# RA register map
Vendor: Renesas; Series: All Chips; File version: x.xx
Registers are 32-bit, read-write, reset 0x0 unless marked. A register's access mark holds for its fields unless they carry their own. Offsets are from the block's base; [hi:lo] are bit positions; lines under a group give offsets from that group; {n}, {i} and the like mark numbered series; 'fields as' and 'values as' point back to an identical list.

## R_GLCDC — Graphics LCD Controller
Base 0x400E0000
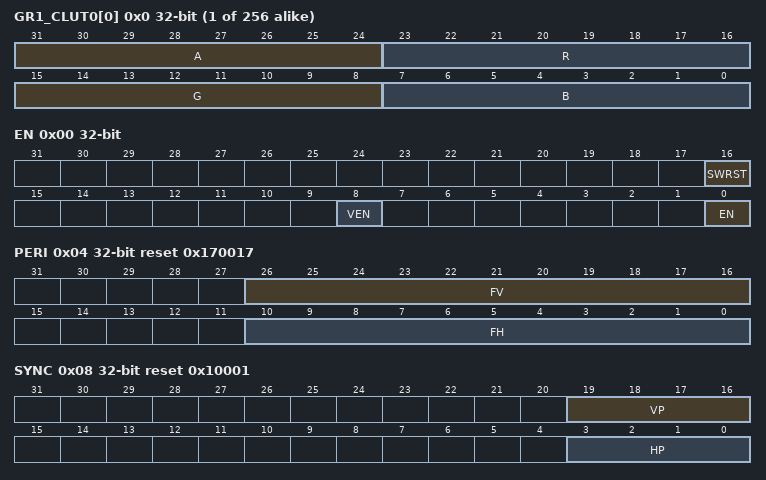
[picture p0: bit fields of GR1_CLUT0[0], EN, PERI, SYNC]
{0x0+4i} GR1_CLUT0[{i}] (i=0..255) reset not defined — Color Palette 0 Plane for Graphics 1 Plane
  [31:24] A — Alpha Blending Value of Color Palette n Plane for Graphics m Plane
  [23:16] R — R Value of Color Palette n Plane for Graphics m Plane
  [15:8] G — G Value of Color Palette n Plane for Graphics m Plane
  [7:0] B — B Value of Color Palette n Plane for Graphics m Plane
0x400 GR1_CLUT1[%s] reset not defined — Color Palette 1 Plane for Graphics 1 Plane
0x800 GR2_CLUT0[%s] reset not defined — Color Palette 0 Plane for Graphics 2 Plane
0xC00 GR2_CLUT1[%s] reset not defined — Color Palette 1 Plane for Graphics 2 Plane
0x1000 BG group — Background Registers
  0x00 EN — Background Plane Setting Operation Control Register
    [16] SWRST — Entire module SW reset control
      1=Releases the entire module from the SW reset state; 0=Places the entire module in the SW reset state
    [8] VEN write-1-sets read-modifies — Control of LCDC internal register value reflection to internal operations
      1=Enables; 0=Disables(Cleared to 0 by an internal source)
    [0] EN — Background plane generation module operation enable
      1=Enables operation; 0=Disables operation
  0x04 PERI reset 0x170017 — Background Plane Setting Free-Running Period Register
    [26:16] FV range 0x013..0x3FF — Background plane vertical synchronization signal period on the basis of line.
      other=FV (FV lines.The valid range is 0x013 to 0x3FF.)
    [10:0] FH range 0x017..0x3FF — Background plane horizontal synchronization signal period on the basis of pixel clock (PXCLK).
      other=FH (FH lines. The valid range is 0x017 to 0x3FF.)
  0x08 SYNC reset 0x10001 — Background Plane Setting Synchronization Position Register
    [19:16] VP — Background plane vertical synchronization signal assertion position on the basis of line.
      0=Setting prohibited; other=others ((VP)th line)
    [3:0] HP — Background plane horizontal synchronization signal assertion position on the basis of pixel clock (PXCLK).
      0=Setting prohibited; other=others ((HP)th line (pixels))
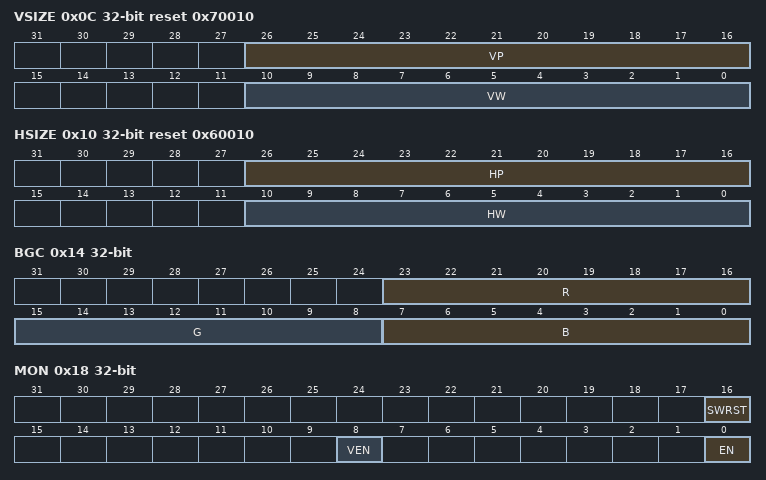
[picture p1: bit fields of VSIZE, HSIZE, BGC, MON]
  0x0C VSIZE reset 0x70010 — Background Plane Setting Full Image Vertical Size Register
    [26:16] VP range 0x0003..0x3EF — Background plane vertical valid pixel start position on the basis of line
      other=VP (VP lines. The valid range is 0x003 to 0x3EF.)
    [10:0] VW range 0x0010..0x03FC — Background plane vertical valid pixel width on the basis of line
      other=VW (VW lines. The valid range is 0x010 to 0x3F0.)
  0x10 HSIZE reset 0x60010 — Background Plane Setting Full Image Horizontal Size Register
    [26:16] HP range 0x006..0x3EE — Background plane horizontal valid pixel start position on the basis of pixel clock (PXCLK).
      other=HP (HP cycle(pixel). The valid range is 0x006 to 0x3EE.)
    [10:0] HW range 0x010..0x3F8 — Background plane horizontall valid pixel width on the basis of pixel clock (PXCLK) Note: When serial RGB is selected as the output format for the output control block, add two to the horizontal enable signal width and set the resulting value to this field.
      other=HW (HW cycles. The valid range is 0x010 to 0x3F8.)
  0x14 BGC — Background Plane Setting Background Color Register
    [23:16] R — R value for background plane valid pixel area. Unsigned; 8-bit integer.
    [15:8] G — G value for background plane valid pixel area Unsigned; 8-bit integer
    [7:0] B — B value for background plane valid pixel area Unsigned; 8-bit integer
  0x18 MON ro — Background Plane Setting Status Monitor Register
    [16] SWRST — Entire module SW reset state monitor.
      1=The entire module is released from the SW reset state; 0=The entire module is in the SW reset state
    [8] VEN — Entire module internal operation reflection control signal monitor. The signal state for controlling reflection of the register values to the internal operations upon assertion of the vertical synchronization signal.
      1=The signal for controlling reflection of the register values to the internal operations upon assertion of the vertical synchronization signal is asserted; 0=The signal for controlling reflection of the register values to the internal operations upon assertion of the vertical synchronization signal is negated
    [0] EN — Background plane generation module operation state monitor.
      1=Operation is in progress; 0=Operation is stopped
{0x1100+0x100*i} GR[{i}] (i=0..1) group — Layer Registers
  0x00 VEN — Graphics Register Update Control Register
    [0] PVEN write-0-clears read-modifies — Control of graphics n module register value reflection to internal operations. Reflection of the register values to the internal operation at the assertion of the vertical synchronization signal (VS).
      1=Enables reflection of the register values to the internal operation at the assertion of the vertical synchronization signal (VS); 0=Disables reflection of the register values to the internal operation at the assertion of the vertical synchronization signal (VS)
  0x04 FLMRD — Graphics Frame Buffer Read Control Register
    [0] RENB — Graphics data (frame buffer data) read enable.
      1=Enables reading; 0=Disables reading
  0x08 FLM1 ro reset 0x3 — Graphics Frame Buffer Control Register 1
    [1:0] BSTMD — Burst transfer control for graphics data (frame buffer data) access
      3=16-beat increment burst transfer (64-byte boundary); other=others (Setting prohibited.)
  0x0C FLM2 — Graphics Frame Buffer Control Register 2
    [31:0] BASE — Base address for accessing graphics data (frame buffer data) Set the head address in the frame buffer where graphics data is to be stored. GRn_FLM2.BASE[5:0] should be fixed to 0 during 64-byte burst transfer.
  0x10 FLM3 — Graphics Frame Buffer Control Register 3
    [31:16] LNOFF — Macro line offset address for accessing graphics data (frame buffer data) Signed; 16-bit integer
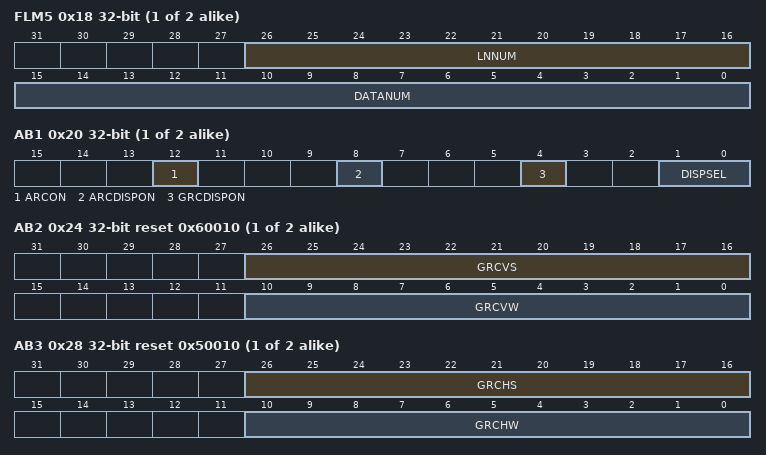
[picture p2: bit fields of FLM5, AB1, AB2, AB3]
  0x18 FLM5 — Graphics Frame Buffer Control Register 5
    [26:16] LNNUM range 0x00F..0x3FF — Number of lines per frame for accessing graphics data (frame buffer data).
      other=LNNUM (LNNUM lines. The valid range is 0x00F to 0x3FF.)
    [15:0] DATANUM — Number of data transfer times per line for accessing graphics data (frame buffer data), where one transfer is defined as 16-beat burst access (64-byte boundary)
      other=DATAUM (DATAUM+1 times.)
  0x1C FLM6 — Graphics Frame Buffer Control Register 6
    [30:28] FORMAT — Data format for accessing graphics data (frame buffer data).
      7=CLUT11bit/pix); 6=CLUT4 (4 bits/pix); 5=CLUT8 (8 bits/pix); 4=ARGB8888 (32 bits/pix); 3=ARGB4444 (16 bits/pix); 2=ARGB1555 (16 bits/pix, 1 bit of A is LUT data); 1=RGB888 (32 bits/pix, 8 bits on the MSB side are invalid); 0=RGB565 (16 bits/pix); other=others (Setting prohibited.)
  0x20 AB1 — Graphics Alpha Blending Control Register 1
    [12] ARCON — Rectangular area alpha blending control.
      1=On; 0=Off
    [8] ARCDISPON — Image area border display control for rectangular area alpha blending.
      1=Display on; 0=Display off
    [4] GRCDISPON — Graphics image area border display control.
      1=Display on; 0=Display off
    [1:0] DISPSEL — Graphics display plane control.
      3=Blended display of lower-layer graphics (input image from the previous stage) and current graphics (graphics data read from the AHB bus); 2=Current graphics display; 1=Lower-layer graphics display; 0=Background color display (value set by the GRn_BASE register)
  0x24 AB2 reset 0x60010 — Graphics Alpha Blending Control Register 2
    [26:16] GRCVS range 0x002..0x3EE — Vertical start position of graphics image area.
      other=GRCVS (GRCVS lines. The valid range is 0x002 to 0x3EE.)
    [10:0] GRCVW range 0x010..0x3FC — Vertical width of graphics image area.
      other=GRCVW (GRCVW lines. The valid range is 0x010 to 0x3F0.)
  0x28 AB3 reset 0x50010 — Graphics Alpha Blending Control Register 3
    [26:16] GRCHS range 0x005..0x3ED — Horizontal start position of graphics image area.
      other=GRCHS (GRCHS lines. The valid range is 0x005 to 0x3ED.)
    [10:0] GRCHW range 0x010..0x3F0 — Horizontal width of graphics image area.
      other=GRCHW (GRCHW pixels. The valid range is 0x010 to 0x3F0.)
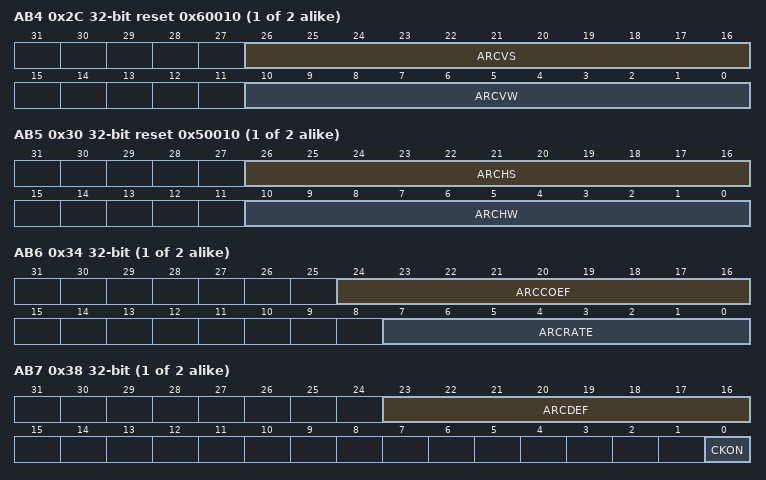
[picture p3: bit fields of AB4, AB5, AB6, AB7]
  0x2C AB4 reset 0x60010 — Graphics Alpha Blending Control Register 4
    [26:16] ARCVS range 0x002..0x3EE — Vertical start position of rectangular area alpha blending image area
      other=ARCVS (ARCVS linels. The valid range is 0x002 to 0x3EE.)
    [10:0] ARCVW range 0x001..0x3FC — Vertical width of rectangular area alpha blending image area.
      other=ARCVW (ARCVW linels. The valid range is 0x001 to 0x3F0.)
  0x30 AB5 reset 0x50010 — Graphics Alpha Blending Control Register 5
    [26:16] ARCHS range 0x005..0x3ED — Horizontal start position of rectangular area alpha blending image area.
      other=ARCHS (ARCHS pixel. The valid range is 0x005 to 0x3ED.)
    [10:0] ARCHW range 0x001..0x3F8 — Horizontal width of rectangular area alpha blending image area.
      other=ARCHW (ARCHW pixels. The valid range is 0x001 to 0x3F0.)
  0x34 AB6 — Graphics Alpha Blending Control Register 6
    [24:16] ARCCOEF — Alpha coefficient for alpha blending in rectangular area (-255 to 255). [8]: Sign (0: addition, 1: subtraction) [7:0]: Variation (absolute value)
    [7:0] ARCRATE — Frame rate for alpha blending in rectangular area.
      other=ARCRATE (ARCRATE+1 frames)
  0x38 AB7 — Graphics Alpha Blending Control Register 7
    [23:16] ARCDEF — Initial alpha value for alpha blending in rectangular area.
    [0] CKON — RGB-index chroma-key processing control.
      1=Enables chroma-key processing; 0=Disables chroma-key processing
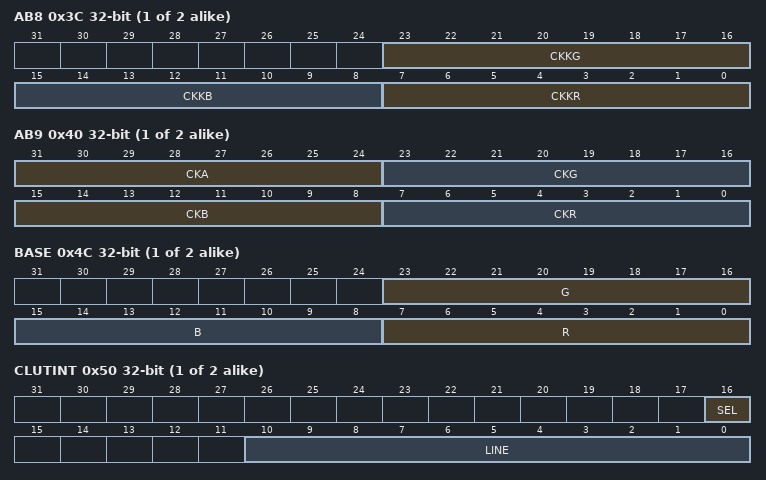
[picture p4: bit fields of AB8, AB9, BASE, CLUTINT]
  0x3C AB8 — Graphics Alpha Blending Control Register 8
    [23:16] CKKG — G signal for RGB-index chroma-key processing Unsigned; 8 bits.
    [15:8] CKKB — B signal for RGB-index chroma-key processing Unsigned; 8 bits.
    [7:0] CKKR — R signal for RGB-index chroma-key processing Unsigned; 8 bits.
  0x40 AB9 — Graphics Alpha Blending Control Register 9
    [31:24] CKA — A value after RGB-index chroma-key processing replacement.
    [23:16] CKG — G value after RGB-index chroma-key processing replacement Unsigned; 8 bits.
    [15:8] CKB — B value after RGB-index chroma-key processing replacement Unsigned; 8 bits.
    [7:0] CKR — R value after RGB-index chroma-key processing replacement Unsigned; 8 bits.
  0x4C BASE — Graphics Background Color Control Register
    [23:16] G — Background color G value Unsigned; 8 bits
    [15:8] B — Background color B value Unsigned; 8 bits
    [7:0] R — Background color R value Unsigned; 8 bits
  0x50 CLUTINT — Graphics CLUT Table Interrupt Control Register
    [16] SEL — CLUT table control
      1=Uses CLUT1 plane for internal operations; 0=Uses CLUT0 plane for internal operations; other=others (Setting prohibited)
    [10:0] LINE range 0x000..0x400 — Number of detection lines
      other=LINE (LINE+1 lines. The valid range is 0x000 to 0x400.)
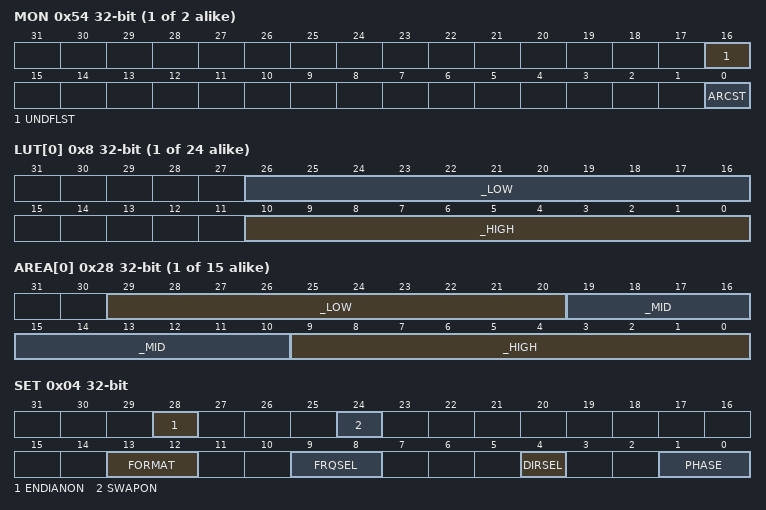
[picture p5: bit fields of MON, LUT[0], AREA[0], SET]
  0x54 MON ro — Graphics Status Monitor Register
    [16] UNDFLST — Status monitor for underflow
      1=An underflow occurs in internal operations; 0=No underflow occurs in internal operations
    [0] ARCST — Status monitor for alpha blending in rectangular area
      1=Fade-in/fade-out is in progress; 0=Fade-in/fade-out is not in progress
{0x1300+0x40*i} GAM[{i}] (i=0..2) group — Gamma Settings
  0x00 LATCH — Gamma Register Update Control Register
    [0] VEN write-0-clears read-modifies — Control of gamma correction x module register value reflection to internal operations. The register values to be reflected to the internal operations at the assertion of the vertical synchronization signal (VS).
      1=Enables the register values to be reflected to the internal operations at the assertion of the vertical synchronization signal (VS); 0=Disables the register values to be reflected to the internal operations at the assertion of the vertical synchronization signal (VS)
  0x04 GAM_SW — Gamma Correction Block Function Switch Register
    [0] GAMON — Gamma correction on/off control
      1=Turns on gamma correction; 0=Turns off gamma correction
  {0x8+4j} LUT[{j}] (j=0..7) — Gamma Correction Block Table Setting Register
    [10:0] _{x} (x=HIGH,LOW; step 16) — Gain value of area 0. Unsigned 11-bit fixed point.
      other=GAIN00 (GAIN00/1024)
  {0x28+4j} AREA[{j}] (j=0..4) — Gamma Correction Block Area Setting Register
    [9:0] _{x} (x=HIGH,MID,LOW; step 10) — Start threshold of area 1 Unsigned 10-bit integer
0x13C0 OUT group — Output Control Registers
  0x00 VLATCH — Output Control Block Register Update Control Register
    [0] VEN write-0-clears read-modifies — Control of output control module register value reflection to internal operations. The register values to be reflected to the internal operations at the assertion of the vertical synchronization signal (VS).
      values as GAM[0].LATCH.VEN
  0x04 SET — Output Control Block Output Interface Register
    [28] ENDIANON — Bit endian change control
      1=Ascending order (big endian); 0=Descending order (little endian)
    [24] SWAPON — Pixel order control
      1=In the order of BGR; 0=In the order of RGB
    [13:12] FORMAT — Output format select
      3=Serial RGB; select RGB888 as dither output format; 2=RGB565; select RGB565 as dither output format; 1=RGB666; select RGB666 as dither output format; 0=RGB888; select RGB888 as dither output format
    [9:8] FRQSEL — Clock frequency division control
      3=Setting prohibited; 2=Quarter frequency (serial RGB); 1=Setting prohibited; 0=No frequency division, parallel RGB
    [4] DIRSEL — Invalid data position control in serial RGB format
      1=Invalid data is output prior to valid (RGB) data; 0=Invalid data is output following valid (RGB) data
    [1:0] PHASE — Data delay in serial RGB format (based on OUTCLK)
      3=3 cycles; 2=2 cycles; 1=1 cycle; 0=0 cycle
  0x08 BRIGHT1 — Output Control Block Brightness Correction Register 1
    [9:0] BRTG — Brightness (DC) adjustment of G signal Unsigned; 10 bits; +512 with offset; integer
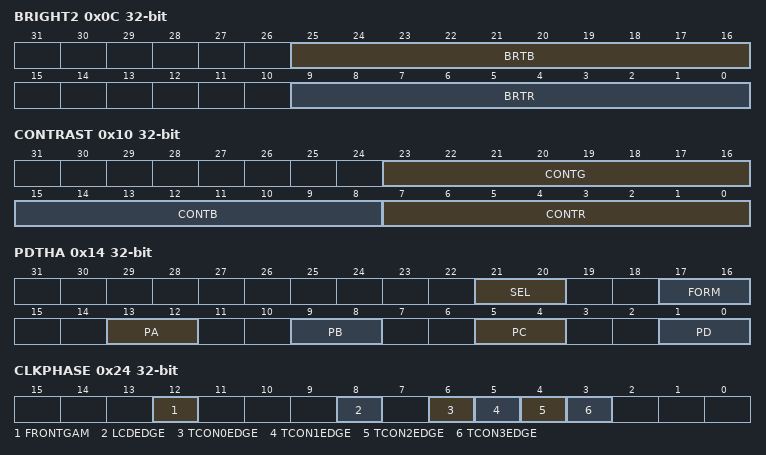
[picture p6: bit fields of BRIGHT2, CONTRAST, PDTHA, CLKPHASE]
  0x0C BRIGHT2 — Output Control Block Brightness Correction Register 2
    [25:16] BRTB — Brightness (DC) adjustment of B signal Unsigned; 10 bits; +512 with offset; integer
    [9:0] BRTR — Brightness (DC) adjustment of R signal Unsigned; 10 bits; +512 with offset; integer
  0x10 CONTRAST — Output Control Block Contrast Correction Register
    [23:16] CONTG — Contrast (GAIN) adjustment of G signal Unsigned; 8 bits fixed point.
      other=CONTG (CONTG/128)
    [15:8] CONTB — Contrast (GAIN) adjustment of B signal Unsigned; 8 bits fixed point
      other=CONTB (CONTB/128)
    [7:0] CONTR — Contrast (GAIN) adjustment of R signal Unsigned; 8 bits fixed point
      other=CONTR (CONTR/128)
  0x14 PDTHA — Output Control Block Panel Dither Correction Register
    [21:20] SEL — Operation mode
      3=Setting prohibited; 2=2x2 pattern dither; 1=Round-off; 0=Truncate
    [17:16] FORM — Output format select
      3=Setting prohibited; 2=RGB565; select RGB565 as output interface format; 1=RGB666; select RGB666 as output interface format; 0=RGB888; select RGB888 or serial RGB as output interface format
    [13:12] PA — Pattern value (A) of 2 x 2 pattern dither Unsigned 2-bit integer
    [9:8] PB — Pattern value (B) of 2 x 2 pattern dither Unsigned 2-bit integer
    [5:4] PC — Pattern value (C) of 2 x 2 pattern dither Unsigned 2-bit integer
    [1:0] PD — Pattern value (D) of 2 x 2 pattern dither Unsigned 2-bit integer
  0x24 CLKPHASE — Output Control Block Output Phase Control Register
    [12] FRONTGAM — Correction control
      1=Gamma correction is followed by brightness/contrast correction; 0=Brightness/contrast correction is followed by gamma correction
    [8] LCDEDGE — LCD_DATA Output Phase Control
      0=In synchronization with the rising edge of LCD_CLK; 1=In synchronization with the falling edge of LCD_CLK
    [6-n] TCON{n}EDGE (n=0..3) — LCD_TCON{n} Output Phase Control
      1=In synchronization with the falling edge of LCD_CLK; 0=In synchronization with the rising edge of LCD_CLK
0x1400 TCON group — Timing Control Registers
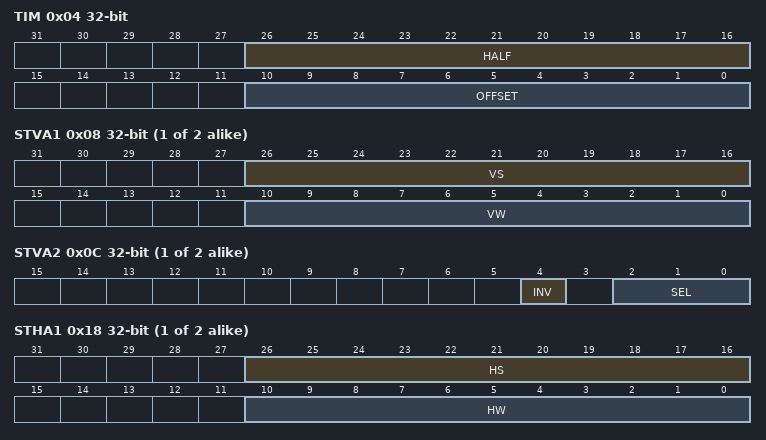
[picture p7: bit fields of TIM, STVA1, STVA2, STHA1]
  0x04 TIM — TCON Reference Timing Setting Register
    [26:16] HALF range 0x000..0x3FF — Vertical synchronization signal generation change timing Sets the delay from the assertion of the internal horizontal synchronization signal in terms of pixels.
      other=HALF (HALF pixels. The valid range is 0x000 to 0x3FF.)
    [10:0] OFFSET range 0x000..0x3FF — Horizontal synchronization signal generation reference timing Sets the offset from the assertion of the internal horizontal synchronization signal in terms of pixels.
      other=OFFSET (OFFSET+1 pixels. The valid range is 0x000 to 0x3FF.)
  0x08 STV{x}1 (x=A,B; step 0x8) — TCON Vertical Timing Setting Register {x}1
    [26:16] VS range 0x000..0x7FF — STVx1 first change timing
      other=VS (VS pixels. The valid range is 0x000 to 0x3FF.)
    [10:0] VW range 0x000..0x7FF — STVx1 second change timing Sets the signal assertion width.
      other=VW (VW pixels. The valid range is 0x000 to 0x3FF.)
  0x0C STV{x}2 (x=A,B; step 0x8) — TCON Vertical Timing Setting Register {x}2
    [4] INV — STVx signal polarity inversion control
      1=Inverted; 0=Not inverted
    [2:0] SEL — Output signal select control for VSOUT (controlled by TCON_STVA2 register)/VEOUT (controlled by the TCON_STVB2 register) pin
      7=DE; 6=Setting prohibited; 5=Setting prohibited; 4=Setting prohibited; 3=STHB; 2=STHA; 1=STVB; 0=STVA
  0x18 STH{x}1 (x=A,B; step 0x8) — TCON Horizontal Timing Setting Register STH{x}1
    [26:16] HS range 0x000..0x3FF — STHx1 first change timing
      other=HS (HS lines. The valid range is 0x000 to 0x3FF.)
    [10:0] HW range 0x000..0x3FF — STHx1 second change timing. Sets the signal assertion width.
      other=HW (HW pixels. The valid range is 0x000 to 0x3FF.)
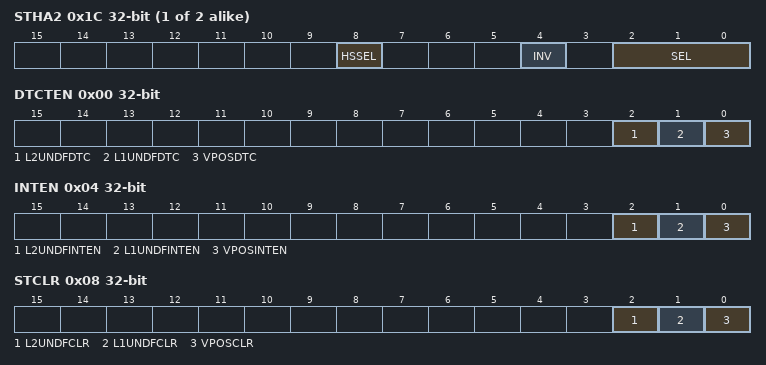
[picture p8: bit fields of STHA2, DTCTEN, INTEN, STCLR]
  0x1C STH{x}2 (x=A,B; step 0x8) — TCON Horizontal Timing Setting Register STH{x}2
    [8] HSSEL — STHx signal generation reference timing control.
      1=Reference timing is the offset set with the TCON_TIM.OFFSET[10:0] (horizontal synchronization generation reference timing) field; 0=Reference timing is the input horizontal synchronization signal (HSIN)
    [4] INV — STVx signal polarity inversion control.
      1=Inverted; 0=Not inverted
    [2:0] SEL — Output signal select control for LCD_TCON2 (controlled by TCON_STHA2 register)/LCD_TCON3 (controlled by the TCON_STHB2 register) pin.
      values as TCON.STV{x}2.SEL
  0x28 DE — TCON Data Enable Polarity Setting Register
    [0] INV — DE signal polarity inversion control.
      1=Inverted; 0=Not inverted
0x1440 SYSCNT group — GLCDC System Control Registers
  0x00 DTCTEN — System control block State Detection Control Register
    [all] fields
      1=Enables detection; 0=Disables detection
    [2] L2UNDFDTC — Graphics 2 underflow detection control
    [1] L1UNDFDTC — Graphics 1 underflow detection control
    [0] VPOSDTC — Specified line detection control
  0x04 INTEN — System control block Interrupt Request Enable Control Register
    [2] L2UNDFINTEN — Interrupt request signal GLCDC_L2UNDF enable control.
      1=Enables GLCDC_L2UNDF output; 0=Disables GLCDC_L2UNDF output
    [1] L1UNDFINTEN — Interrupt request signal GLCDC_L1UNDF enable control.
      1=Enables GLCDC_L1UNDF output; 0=Disables GLCDC_L1UNDF output
    [0] VPOSINTEN — Interrupt request signal GLCDC_VPOS enable control.
      1=Enables GLCDC_VPOS output; 0=Disables GLCDC_VPOS output
  0x08 STCLR — System control block Status Clear Register
    [2] L2UNDFCLR — Graphics 2 underflow detection flag clear field
      1=Clears the graphics 2 underflow detection flag; 0=No operation
    [1] L1UNDFCLR — Graphics 1 underflow detection flag clear field
      1=Clears the graphics 1 underflow detection flag; 0=No operation
    [0] VPOSCLR — Graphics 2 specified line detection flag clear field
      1=Clears the specified line detection flag; 0=No operation
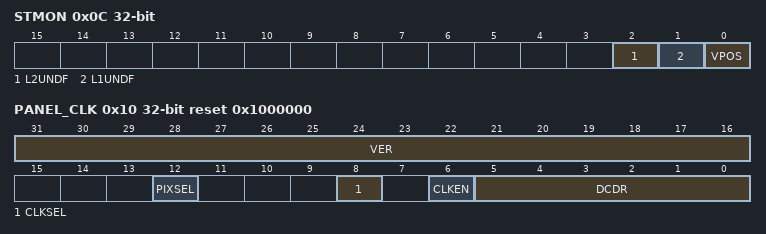
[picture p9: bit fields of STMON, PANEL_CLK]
  0x0C STMON ro — System control block Status Monitor Register
    [2] L2UNDF — Graphics 2 underflow detection flag
      1=An underflow has been detected in graphics 2; 0=No underflow has been detected in graphics 2
    [1] L1UNDF — Graphics 1 underflow detection flag
      1=An underflow has been detected in graphics 1; 0=No underflow has been detected in graphics 1
    [0] VPOS — Graphics 2 specified line detection flag
      1=A specified line notification has been detected in graphics 2; 0=No specified line notification has been detected in graphics 2
  0x10 PANEL_CLK reset 0x1000000 — System control block Version and Panel Clock Control Register
    [31:16] VER ro — Version information Version information of the GLCDC
    [12] PIXSEL — Pixel clock select control. Must be set to the same value as OUT_SET.FRQSEL[1].
      0=No frequency division, parallel RGB; 1=Quarter frequency,serial RGB
    [8] CLKSEL — Panel clock supply source select
      0=External clock select; 1=PLL output select
    [6] CLKEN — Panel clock output enable control Note: Before changing the PIXSEL,CLKSEL or DCDR bit, this bit must be set to 0.
      0=Disable panel clock output; 1=Enable panel clock output
    [5:0] DCDR — Clock division ratio setting control Refer toTable 2.7.1 for details about setting value. Note: Settings that are not listed in table 2.7.1 are prohibited.
